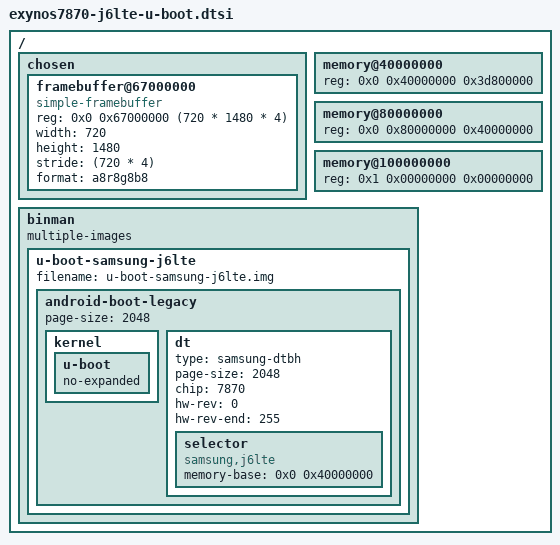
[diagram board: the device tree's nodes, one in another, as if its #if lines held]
// SPDX-License-Identifier: GPL-2.0
/*
 * Copyright (c) Kaustabh Chakraborty <kauschluss@disroot.org>
 */

#include <config.h>

/ {
	chosen {
		#address-cells = <2>;
		#size-cells = <1>;
		ranges;

		framebuffer@67000000 {
			compatible = "simple-framebuffer";
			reg = <0x0 0x67000000 (720 * 1480 * 4)>;
			width = <720>;
			height = <1480>;
			stride = <(720 * 4)>;
			format = "a8r8g8b8";
		};
	};

	/*
	 * S-BOOT will populate the memory nodes stated below. Existing
	 * values redefine the safe memory requirements as stated in upstream
	 * device tree, in separate nodes for each bank.
	 */
	memory@40000000 {
		device_type = "memory";
		reg = <0x0 0x40000000 0x3d800000>;
	};

	memory@80000000 {
		device_type = "memory";
		reg = <0x0 0x80000000 0x40000000>;
	};

	memory@100000000 {
		device_type = "memory";
		reg = <0x1 0x00000000 0x00000000>;
	};
};

#ifdef CONFIG_SAMSUNG_EXYNOS_LEGACY_BOOT_IMAGE
/ {
	binman: binman {
		multiple-images;

		u-boot-samsung-j6lte {
			filename = "u-boot-samsung-j6lte.img";

			android-boot-legacy {
				page-size = <2048>;

				kernel {
					u-boot {
						no-expanded;
					};
				};

				dt {
					type = "samsung-dtbh";
					page-size = <2048>;
					chip = <7870>;
					hw-rev = <0>;
					hw-rev-end = <255>;

					selector {
						compatible = "samsung,j6lte",
							     "samsung,exynos7870";
						memory-base = <0x0 0x40000000>;
					};
				};
			};
		};
	};
};
#endif
